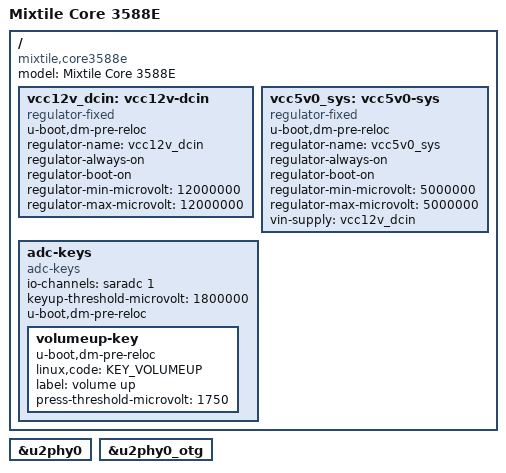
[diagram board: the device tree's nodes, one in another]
// SPDX-License-Identifier: (GPL-2.0+ OR MIT)
/*
 * Copyright (c) 2021 Rockchip Electronics Co., Ltd
 *
 */

/dts-v1/;
#include "rk3588.dtsi"
#include "rk3588-u-boot.dtsi"
#include <dt-bindings/input/input.h>

/ {
	model = "Mixtile Core 3588E";
	compatible = "mixtile,core3588e", "rockchip,rk3588";

	vcc12v_dcin: vcc12v-dcin {
		u-boot,dm-pre-reloc;
		compatible = "regulator-fixed";
		regulator-name = "vcc12v_dcin";
		regulator-always-on;
		regulator-boot-on;
		regulator-min-microvolt = <12000000>;
		regulator-max-microvolt = <12000000>;
	};

	vcc5v0_sys: vcc5v0-sys {
		u-boot,dm-pre-reloc;
		compatible = "regulator-fixed";
		regulator-name = "vcc5v0_sys";
		regulator-always-on;
		regulator-boot-on;
		regulator-min-microvolt = <5000000>;
		regulator-max-microvolt = <5000000>;
		vin-supply = <&vcc12v_dcin>;
	};

	adc-keys {
		compatible = "adc-keys";
		io-channels = <&saradc 1>;
		io-channel-names = "buttons";
		keyup-threshold-microvolt = <1800000>;
		u-boot,dm-pre-reloc;
		status = "okay";

		volumeup-key {
			u-boot,dm-pre-reloc;
			linux,code = <KEY_VOLUMEUP>;
			label = "volume up";
			press-threshold-microvolt = <1750>;
		};
	};
};

&u2phy0 {
	status = "okay";
};

&u2phy0_otg {
	status = "okay";
};
